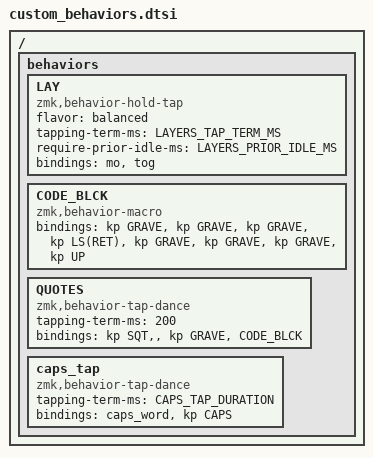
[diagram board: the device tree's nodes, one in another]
#define LAYERS_QUICK_TAP_MS 280
#define LAYERS_TAP_TERM_MS 175
#define LAYERS_PRIOR_IDLE_MS 150
#define CAPS_TAP_DURATION 150

ZMK_HOLD_TAP(LAY,
    flavor = "balanced";
    tapping-term-ms = <LAYERS_TAP_TERM_MS>;
    require-prior-idle-ms = <LAYERS_PRIOR_IDLE_MS>;
    bindings = <&mo>, <&tog>;
)

#define NUM LAY NUMBERS NUMBERS
#define SYM LAY SYMBOLS SYMBOLS
#define NAV LAY NAVIGATION NAVIGATION
#define MED LAY MEDIA MEDIA
#define FUNC LAY FUNCTION FUNCTION

ZMK_MACRO(CODE_BLCK,
    bindings = <
                &kp GRAVE &kp GRAVE &kp GRAVE &kp LS(RET)
                &kp GRAVE &kp GRAVE &kp GRAVE &kp UP
            >;
)

ZMK_TAP_DANCE(QUOTES,
    tapping-term-ms = <200>;
    bindings = <&kp SQT, <&kp GRAVE>, <CODE_BLCK>;
)

/ {

    behaviors {

        caps_tap: caps_tap {
            compatible = "zmk,behavior-tap-dance";
            #binding-cells = <0>;
            tapping-term-ms = <CAPS_TAP_DURATION>;
            bindings = <&caps_word>, <&kp CAPS>;
        };
	};
};
